# STM32F7x6 register map
File version: 1.3
CPU: CM7 r0p0, little endian, no MPU, no FPU, 3 interrupt priority bits
Registers are 32-bit, read-write, reset 0x0 unless marked. A register's access mark holds for its fields unless they carry their own. Offsets are from the block's base; [hi:lo] are bit positions.

## IWDG — Independent watchdog
Base 0x40003000
0x00 KR wo — Key register
  [15:0] KEY — Key value (write only, read 0000h)
0x04 PR — Prescaler register
  [2:0] PR — Prescaler divider
0x08 RLR reset 0xFFF — Reload register
  [11:0] RL — Watchdog counter reload value
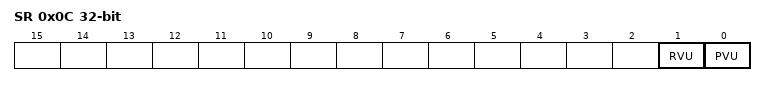
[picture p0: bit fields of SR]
0x0C SR ro — Status register
  [1] RVU — Watchdog counter reload value update
  [0] PVU — Watchdog prescaler value update
0x10 WINR — Window register
  [11:0] WIN — Watchdog counter window value

## WWDG — Window watchdog
Base 0x40002C00
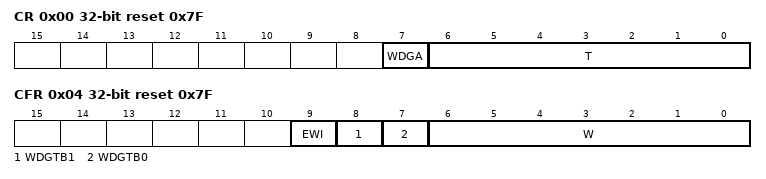
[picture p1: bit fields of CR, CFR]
0x00 CR reset 0x7F — Control register
  [7] WDGA — Activation bit
  [6:0] T — 7-bit counter (MSB to LSB)
0x04 CFR reset 0x7F — Configuration register
  [9] EWI — Early wakeup interrupt
  [8] WDGTB1 — Timer base
  [7] WDGTB0 — Timer base
  [6:0] W — 7-bit window value
0x08 SR — Status register
  [0] EWIF — Early wakeup interrupt flag

## C_ADC — Common ADC registers
Base 0x40012300
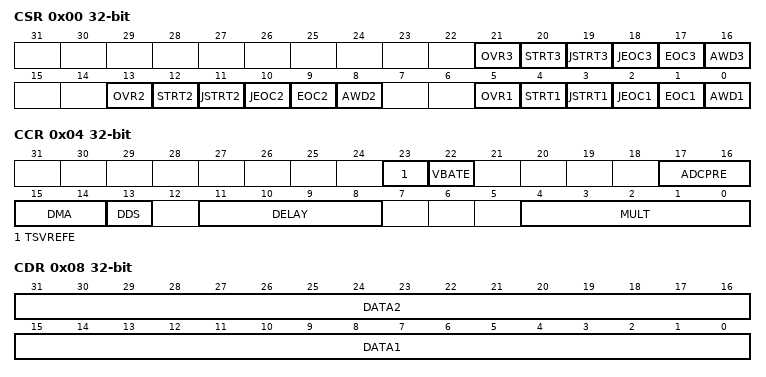
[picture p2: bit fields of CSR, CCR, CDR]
0x00 CSR ro — ADC Common status register
  [21] OVR3 — Overrun flag of ADC3
  [20] STRT3 — Regular channel Start flag of ADC 3
  [19] JSTRT3 — Injected channel Start flag of ADC 3
  [18] JEOC3 — Injected channel end of conversion of ADC 3
  [17] EOC3 — End of conversion of ADC 3
  [16] AWD3 — Analog watchdog flag of ADC 3
  [13] OVR2 — Overrun flag of ADC 2
  [12] STRT2 — Regular channel Start flag of ADC 2
  [11] JSTRT2 — Injected channel Start flag of ADC 2
  [10] JEOC2 — Injected channel end of conversion of ADC 2
  [9] EOC2 — End of conversion of ADC 2
  [8] AWD2 — Analog watchdog flag of ADC 2
  [5] OVR1 — Overrun flag of ADC 1
  [4] STRT1 — Regular channel Start flag of ADC 1
  [3] JSTRT1 — Injected channel Start flag of ADC 1
  [2] JEOC1 — Injected channel end of conversion of ADC 1
  [1] EOC1 — End of conversion of ADC 1
  [0] AWD1 — Analog watchdog flag of ADC 1
0x04 CCR — ADC common control register
  [23] TSVREFE — Temperature sensor and VREFINT enable
  [22] VBATE — VBAT enable
  [17:16] ADCPRE — ADC prescaler
  [15:14] DMA — Direct memory access mode for multi ADC mode
  [13] DDS — DMA disable selection for multi-ADC mode
  [11:8] DELAY — Delay between 2 sampling phases
  [4:0] MULT — Multi ADC mode selection
0x08 CDR ro — ADC common regular data register for dual and triple modes
  [31:16] DATA2 — 2nd data item of a pair of regular conversions
  [15:0] DATA1 — 1st data item of a pair of regular conversions

## TIM9 — General purpose timers
Base 0x40014000
Same registers: TIM12 0x40001800
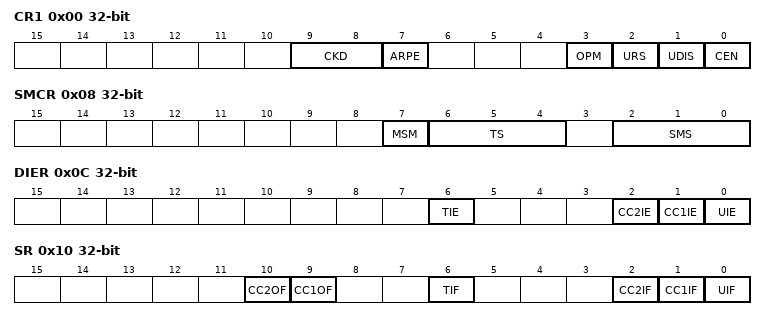
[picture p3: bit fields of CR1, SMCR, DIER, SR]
0x00 CR1 — control register 1
  [9:8] CKD — Clock division
  [7] ARPE — Auto-reload preload enable
  [3] OPM — One-pulse mode
  [2] URS — Update request source
  [1] UDIS — Update disable
  [0] CEN — Counter enable
0x08 SMCR — slave mode control register
  [7] MSM — Master/Slave mode
  [6:4] TS — Trigger selection
  [2:0] SMS — Slave mode selection
0x0C DIER — DMA/Interrupt enable register
  [6] TIE — Trigger interrupt enable
  [2] CC2IE — Capture/Compare 2 interrupt enable
  [1] CC1IE — Capture/Compare 1 interrupt enable
  [0] UIE — Update interrupt enable
0x10 SR — status register
  [10] CC2OF — Capture/compare 2 overcapture flag
  [9] CC1OF — Capture/Compare 1 overcapture flag
  [6] TIF — Trigger interrupt flag
  [2] CC2IF — Capture/Compare 2 interrupt flag
  [1] CC1IF — Capture/compare 1 interrupt flag
  [0] UIF — Update interrupt flag
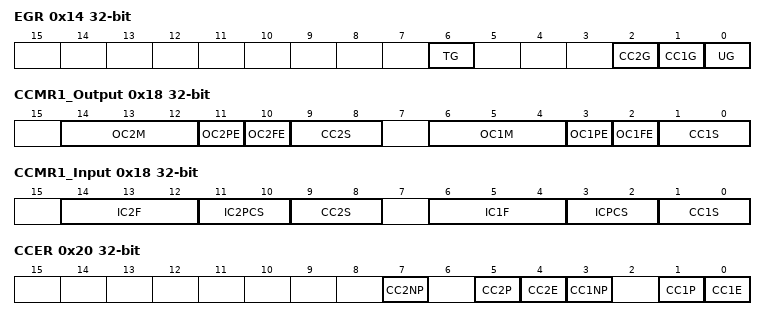
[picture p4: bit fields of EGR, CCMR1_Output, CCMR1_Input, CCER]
0x14 EGR wo — event generation register
  [6] TG — Trigger generation
  [2] CC2G — Capture/compare 2 generation
  [1] CC1G — Capture/compare 1 generation
  [0] UG — Update generation
0x18 CCMR1_Output — capture/compare mode register 1 (output mode)
  [14:12] OC2M — Output Compare 2 mode
  [11] OC2PE — Output Compare 2 preload enable
  [10] OC2FE — Output Compare 2 fast enable
  [9:8] CC2S — Capture/Compare 2 selection
  [6:4] OC1M — Output Compare 1 mode
  [3] OC1PE — Output Compare 1 preload enable
  [2] OC1FE — Output Compare 1 fast enable
  [1:0] CC1S — Capture/Compare 1 selection
0x18 CCMR1_Input (alternate view of CCMR1_Output) — capture/compare mode register 1 (input mode)
  [14:12] IC2F — Input capture 2 filter
  [11:10] IC2PCS — Input capture 2 prescaler
  [9:8] CC2S — Capture/Compare 2 selection
  [6:4] IC1F — Input capture 1 filter
  [3:2] ICPCS — Input capture 1 prescaler
  [1:0] CC1S — Capture/Compare 1 selection
0x20 CCER — capture/compare enable register
  [7] CC2NP — Capture/Compare 2 output Polarity
  [5] CC2P — Capture/Compare 2 output Polarity
  [4] CC2E — Capture/Compare 2 output enable
  [3] CC1NP — Capture/Compare 1 output Polarity
  [1] CC1P — Capture/Compare 1 output Polarity
  [0] CC1E — Capture/Compare 1 output enable
0x24 CNT — counter
  [15:0] CNT — counter value
0x28 PSC — prescaler
  [15:0] PSC — Prescaler value
0x2C ARR — auto-reload register
  [15:0] ARR — Auto-reload value
0x34 CCR1 — capture/compare register 1
  [15:0] CCR1 — Capture/Compare 1 value
0x38 CCR2 — capture/compare register 2
  [15:0] CCR2 — Capture/Compare 2 value
